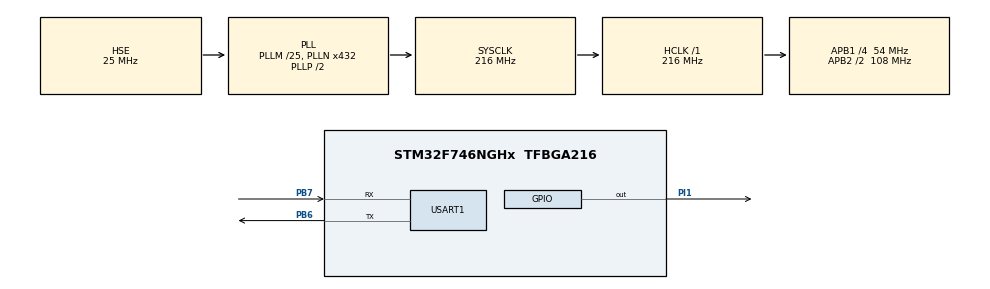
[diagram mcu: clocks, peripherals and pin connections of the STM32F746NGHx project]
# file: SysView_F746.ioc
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FREERTOS.BinarySemaphores01=TrcBinarySem,Dynamic,NULL
FREERTOS.Mutexes01=TrcMutex,Dynamic,NULL
FREERTOS.Tasks01=myTask01,0,256,StartTask01,Default,NULL,Dynamic,NULL,NULL;myTask02,0,256,StartTask02,Default,NULL,Dynamic,NULL,NULL
FREERTOS.configMINIMAL_STACK_SIZE=256
Mcu.Family=STM32F7
Mcu.Name=STM32F746NGHx
Mcu.Package=TFBGA216
NVIC.PriorityGroup=NVIC_PRIORITYGROUP_4
NVIC.TIM1_UP_TIM10_IRQn=true\:0\:0\:false\:false\:true\:false\:false\:true
NVIC.TimeBase=TIM1_UP_TIM10_IRQn
NVIC.TimeBaseIP=TIM1
PA13.Mode=Serial_Wire
PA13.Signal=SYS_JTMS-SWDIO
PA14.Mode=Serial_Wire
PA14.Signal=SYS_JTCK-SWCLK
PB6.Mode=Asynchronous
PB6.Signal=USART1_TX
PB7.Mode=Asynchronous
PB7.Signal=USART1_RX
PH0/OSC_IN.Mode=HSE-External-Oscillator
PH0/OSC_IN.Signal=RCC_OSC_IN
PH1/OSC_OUT.Mode=HSE-External-Oscillator
PH1/OSC_OUT.Signal=RCC_OSC_OUT
PI1.Signal=GPIO_Output
ProjectManager.HeapSize=0x2000
ProjectManager.StackSize=0x4000
ProjectManager.TargetToolchain=STM32CubeIDE
RCC.AHBFreq_Value=216000000
RCC.APB1CLKDivider=RCC_HCLK_DIV4
RCC.APB1Freq_Value=54000000
RCC.APB1TimFreq_Value=108000000
RCC.APB2CLKDivider=RCC_HCLK_DIV2
RCC.APB2Freq_Value=108000000
RCC.APB2TimFreq_Value=216000000
RCC.CortexFreq_Value=216000000
RCC.HCLKFreq_Value=216000000
RCC.HSE_VALUE=25000000
RCC.HSI_VALUE=16000000
RCC.LSE_VALUE=32768
RCC.PLLM=25
RCC.PLLN=432
RCC.PLLSourceVirtual=RCC_PLLSOURCE_HSE
RCC.SYSCLKFreq_VALUE=216000000
RCC.SYSCLKSource=RCC_SYSCLKSOURCE_PLLCLK
RCC.USBFreq_Value=216000000
RCC.VCOOutputFreq_Value=432000000
USART1.VirtualMode-Asynchronous=VM_ASYNC
VP_FREERTOS_VS_CMSIS_V1.Mode=CMSIS_V1
VP_SYS_VS_tim1.Mode=TIM1
board=custom

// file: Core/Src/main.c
/* USER CODE BEGIN Header */
/**
  ******************************************************************************
  * @file           : main.c
  * @brief          : Main program body
  ******************************************************************************
  * @attention
  *
  * <h2><center>&copy; Copyright (c) 2021 STMicroelectronics.
  * All rights reserved.</center></h2>
  *
  * This software component is licensed by ST under BSD 3-Clause license,
  * the "License"; You may not use this file except in compliance with the
  * License. You may obtain a copy of the License at:
  *                        opensource.org/licenses/BSD-3-Clause
  *
  ******************************************************************************
  */
/* USER CODE END Header */
#include "main.h"
#include "cmsis_os.h"
#include "usart.h"
#include "gpio.h"

void SystemClock_Config(void);
void MX_FREERTOS_Init(void);

int main(void)
{
  /* USER CODE BEGIN 1 */

	DWT->CTRL |= (1<<0);

  /* USER CODE END 1 */

  /* MCU Configuration--------------------------------------------------------*/

  /* Reset of all peripherals, Initializes the Flash interface and the Systick. */
  HAL_Init();

  /* Configure the system clock */
  SystemClock_Config();

  /* Initialize all configured peripherals */
  MX_GPIO_Init();
  MX_USART1_UART_Init();
  /* USER CODE BEGIN 2 */

  SEGGER_SYSVIEW_Conf();
  vSetVarulMaxPRIGROUPValue();
  SEGGER_SYSVIEW_Start();

  /* USER CODE END 2 */

  /* Call init function for freertos objects (in freertos.c) */
  MX_FREERTOS_Init();
  /* Start scheduler */
  osKernelStart();

  /* We should never get here as control is now taken by the scheduler */
  /* Infinite loop */
  while (1)
  {

  }
}

void SystemClock_Config(void)
{
  RCC_OscInitTypeDef RCC_OscInitStruct = {0};
  RCC_ClkInitTypeDef RCC_ClkInitStruct = {0};
  RCC_PeriphCLKInitTypeDef PeriphClkInitStruct = {0};

  /** Configure the main internal regulator output voltage
  */
  __HAL_RCC_PWR_CLK_ENABLE();
  __HAL_PWR_VOLTAGESCALING_CONFIG(PWR_REGULATOR_VOLTAGE_SCALE1);
  /** Initializes the RCC Oscillators according to the specified parameters
  * in the RCC_OscInitTypeDef structure.
  */
  RCC_OscInitStruct.OscillatorType = RCC_OSCILLATORTYPE_HSE;
  RCC_OscInitStruct.HSEState = RCC_HSE_ON;
  RCC_OscInitStruct.PLL.PLLState = RCC_PLL_ON;
  RCC_OscInitStruct.PLL.PLLSource = RCC_PLLSOURCE_HSE;
  RCC_OscInitStruct.PLL.PLLM = 25;
  RCC_OscInitStruct.PLL.PLLN = 432;
  RCC_OscInitStruct.PLL.PLLP = RCC_PLLP_DIV2;
  RCC_OscInitStruct.PLL.PLLQ = 2;
  if (HAL_RCC_OscConfig(&RCC_OscInitStruct) != HAL_OK)
  {
    Error_Handler();
  }
  /** Activate the Over-Drive mode
  */
  if (HAL_PWREx_EnableOverDrive() != HAL_OK)
  {
    Error_Handler();
  }
  /** Initializes the CPU, AHB and APB buses clocks
  */
  RCC_ClkInitStruct.ClockType = RCC_CLOCKTYPE_HCLK|RCC_CLOCKTYPE_SYSCLK
                              |RCC_CLOCKTYPE_PCLK1|RCC_CLOCKTYPE_PCLK2;
  RCC_ClkInitStruct.SYSCLKSource = RCC_SYSCLKSOURCE_PLLCLK;
  RCC_ClkInitStruct.AHBCLKDivider = RCC_SYSCLK_DIV1;
  RCC_ClkInitStruct.APB1CLKDivider = RCC_HCLK_DIV4;
  RCC_ClkInitStruct.APB2CLKDivider = RCC_HCLK_DIV2;

  if (HAL_RCC_ClockConfig(&RCC_ClkInitStruct, FLASH_LATENCY_7) != HAL_OK)
  {
    Error_Handler();
  }
  PeriphClkInitStruct.PeriphClockSelection = RCC_PERIPHCLK_USART1;
  PeriphClkInitStruct.Usart1ClockSelection = RCC_USART1CLKSOURCE_PCLK2;
  if (HAL_RCCEx_PeriphCLKConfig(&PeriphClkInitStruct) != HAL_OK)
  {
    Error_Handler();
  }
}

 /**
  * @brief  Period elapsed callback in non blocking mode
  * @note   This function is called  when TIM1 interrupt took place, inside
  * HAL_TIM_IRQHandler(). It makes a direct call to HAL_IncTick() to increment
  * a global variable "uwTick" used as application time base.
  * @param  htim : TIM handle
  * @retval None
  */
void HAL_TIM_PeriodElapsedCallback(TIM_HandleTypeDef *htim)
{
  if (htim->Instance == TIM1) {
    HAL_IncTick();
  }
}

void Error_Handler(void)
{
  __disable_irq();
  while (1)
  {
  }
}

/************************ (C) COPYRIGHT STMicroelectronics *****END OF FILE****/

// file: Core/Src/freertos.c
/* USER CODE BEGIN Header */
/**
  ******************************************************************************
  * File Name          : freertos.c
  * Description        : Code for freertos applications
  ******************************************************************************
  * @attention
  *
  * <h2><center>&copy; Copyright (c) 2021 STMicroelectronics.
  * All rights reserved.</center></h2>
  *
  * This software component is licensed by ST under Ultimate Liberty license
  * SLA0044, the "License"; You may not use this file except in compliance with
  * the License. You may obtain a copy of the License at:
  *                             www.st.com/SLA0044
  *
  ******************************************************************************
  */
/* USER CODE END Header */

#include "FreeRTOS.h"
#include "task.h"
#include "main.h"
#include "cmsis_os.h"

osThreadId myTask01Handle;
osThreadId myTask02Handle;
osMutexId TrcMutexHandle;
osSemaphoreId TrcBinarySemHandle;

void StartTask01(void const * argument);
void StartTask02(void const * argument);

void MX_FREERTOS_Init(void); /* (MISRA C 2004 rule 8.1) */

/* GetIdleTaskMemory prototype (linked to static allocation support) */
void vApplicationGetIdleTaskMemory( StaticTask_t **ppxIdleTaskTCBBuffer, StackType_t **ppxIdleTaskStackBuffer, uint32_t *pulIdleTaskStackSize );

/* USER CODE BEGIN GET_IDLE_TASK_MEMORY */
static StaticTask_t xIdleTaskTCBBuffer;
static StackType_t xIdleStack[configMINIMAL_STACK_SIZE];

void vApplicationGetIdleTaskMemory( StaticTask_t **ppxIdleTaskTCBBuffer, StackType_t **ppxIdleTaskStackBuffer, uint32_t *pulIdleTaskStackSize )
{
  *ppxIdleTaskTCBBuffer = &xIdleTaskTCBBuffer;
  *ppxIdleTaskStackBuffer = &xIdleStack[0];
  *pulIdleTaskStackSize = configMINIMAL_STACK_SIZE;
  /* place for user code */
}
/* USER CODE END GET_IDLE_TASK_MEMORY */

void MX_FREERTOS_Init(void) {
  /* Create the mutex(es) */
  /* definition and creation of TrcMutex */
  osMutexDef(TrcMutex);
  TrcMutexHandle = osMutexCreate(osMutex(TrcMutex));

  /* Create the semaphores(s) */
  /* definition and creation of TrcBinarySem */
  osSemaphoreDef(TrcBinarySem);
  TrcBinarySemHandle = osSemaphoreCreate(osSemaphore(TrcBinarySem), 1);

  /* Create the thread(s) */
  /* definition and creation of myTask01 */
  osThreadDef(myTask01, StartTask01, osPriorityNormal, 0, 256);
  myTask01Handle = osThreadCreate(osThread(myTask01), NULL);

  /* definition and creation of myTask02 */
  osThreadDef(myTask02, StartTask02, osPriorityNormal, 0, 256);
  myTask02Handle = osThreadCreate(osThread(myTask02), NULL);

}

void StartTask01(void const * argument)
{
  /* USER CODE BEGIN StartTask01 */
  /* Infinite loop */
	uint32_t delay = 1;
  for(;;)
  {
	  if(xSemaphoreTake(TrcMutexHandle, ( TickType_t ) 1) == pdTRUE){

		HAL_GPIO_TogglePin(GPIOI, GPIO_PIN_1);
		SEGGER_SYSVIEW_PrintfHost("Task1, delay = %d ms", delay);
		osDelay(delay++);
		xSemaphoreGive(TrcMutexHandle);
		osThreadYield();
	  }
  }
  /* USER CODE END StartTask01 */
}

void StartTask02(void const * argument)
{
  /* USER CODE BEGIN StartTask02 */
  /* Infinite loop */
  for(;;)
  {
	  if(xSemaphoreTake(TrcMutexHandle, ( TickType_t ) 1) == pdTRUE){

		  SEGGER_SYSVIEW_PrintfHost("Task 2, delay = 100 ms");
		  xSemaphoreGive(TrcMutexHandle);
		  osDelay(100);
	  }
  }
  /* USER CODE END StartTask02 */
}

/************************ (C) COPYRIGHT STMicroelectronics *****END OF FILE****/
